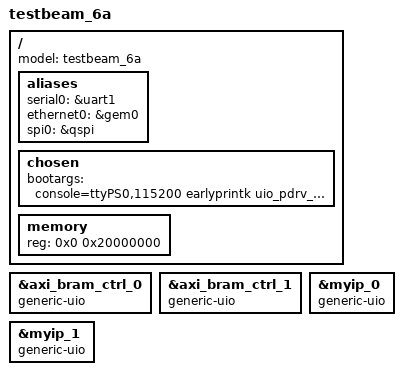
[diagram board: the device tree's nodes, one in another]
/dts-v1/;
/include/ "system-conf.dtsi"
/ {
};

/ {
        model = "testbeam_6a";
        aliases {
                serial0 = &uart1;
                ethernet0 = &gem0;
                spi0 = &qspi;
        };
        chosen {
                bootargs = "console=ttyPS0,115200 earlyprintk uio_pdrv_genirq.of_id=generic-uio";
        };
        memory {
                device_type = "memory";
                reg = <0x0 0x20000000>;
        };
};

&axi_bram_ctrl_0 {
        compatible = "generic-uio";
};

&axi_bram_ctrl_1 {
        compatible = "generic-uio";
};

&myip_0 {
        compatible = "generic-uio";
};

&myip_1 {
        compatible = "generic-uio";
};
